# STM32MP21_CM33 register map
File version: 0.4
CPU: CM33 r0p1, little endian, MPU, FPU, vendor SysTick, 8 interrupt priority bits
Registers are 32-bit, read-write, reset 0x0 unless marked. A register's access mark holds for its fields unless they carry their own. Offsets are from the block's base; [hi:lo] are bit positions; 'fields as' and 'values as' point back to an identical list.

## RAMCFG — RAMCFG register bank
Base 0x42070000
Same registers: RAMCFG_S 0x52070000
0x00 RAMCFG_SYSRAMCR — RAMCFG SYSRAM control register
  [8] SRAMER — SRAM erase
    0=No erase operation ongoing; 1=Erase operation ongoing
0x08 RAMCFG_SYSRAMISR ro — RAMCFG SYSRAM interrupt status register
  [8] SRAMBUSY — SRAM busy with erase operation
    0=No erase operation ongoing; 1=Erase operation ongoing
0x28 RAMCFG_SYSRAMERKEYR wo — RAMCFG SYSRAM erase key register
  [7:0] ERASEKEY — Erase write protection key
0x80 RAMCFG_SRAM1CR — RAMCFG SRAM1 control register
  [8] SRAMER — SRAM erase.
    0=No erase operation ongoing; 1=Erase operation ongoing
0x88 RAMCFG_SRAM1ISR ro — RAMCFG SRAM1 interrupt status register
  fields as RAMCFG_SYSRAMISR
0xA8 RAMCFG_SRAM1ERKEYR wo — RAMCFG SRAM1 erase key register
  [7:0] ERASEKEY — Erase write protection key
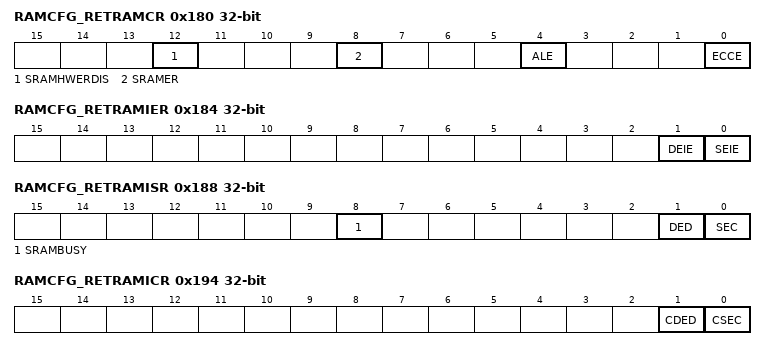
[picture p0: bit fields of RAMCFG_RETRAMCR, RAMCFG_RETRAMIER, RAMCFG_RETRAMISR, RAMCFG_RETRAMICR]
0x180 RAMCFG_RETRAMCR — RAMCFG RETRAM control register
  [12] SRAMHWERDIS — SRAM hardware erase disable
    0=Erase operation done after a system reset; 1=No erase operation done after a system reset
  [8] SRAMER — SRAM erase.
    0=No erase operation ongoing; 1=Erase operation ongoing
  [4] ALE — Address latch enable
    0=Failing address not stored in the RETRAMECC single/double error address registers; 1=Failing address stored in the RETRAMECC single/double error address registers
  [0] ECCE — ECC enable
    0=ECC disabled; 1=ECC enabled
0x184 RAMCFG_RETRAMIER — RAMCFG RETRAM interrupt enable register
  [1] DEIE — ECC double error interrupt enable
    0=Double error interrupt disabled; 1=Double error interrupt enabled
  [0] SEIE — ECC single error interrupt enable
    0=Single error interrupt disabled; 1=Single error interrupt enabled
0x188 RAMCFG_RETRAMISR ro — RAMCFG RETRAM interrupt status register
  [8] SRAMBUSY — SRAM busy with erase operation
    0=No erase operation ongoing; 1=Erase operation ongoing
  [1] DED — ECC double error detected
    0=No double error; 1=Double error detected
  [0] SEC — ECC single error corrected
    0=No single error; 1=Single error corrected
0x18C RAMCFG_RETRAMSEAR ro — RAMCFG RETRAM ECC single error address register
  [14:0] ESEA — ECC single error address
0x190 RAMCFG_RETRAMDEAR ro — RAMCFG RETRAM ECC double error address register
  [14:0] EDEA — ECC double error address
0x194 RAMCFG_RETRAMICR wo — RAMCFG RETRAM interrupt clear flag register
  [1] CDED — Clear of ECC double error detected
  [0] CSEC — Clear of ECC single corrected
0x1A4 RAMCFG_RETRAMECCKEYR wo — RAMCFG RETRAM ECC key register
  [7:0] ECCKEY — ECC write protection key
0x1A8 RAMCFG_RETRAMERKEYR wo — RAMCFG RETRAM erase key register
  [7:0] ERASEKEY — Erase write protection key
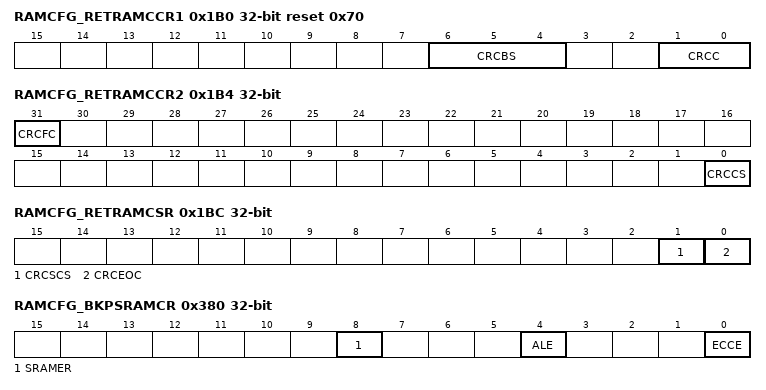
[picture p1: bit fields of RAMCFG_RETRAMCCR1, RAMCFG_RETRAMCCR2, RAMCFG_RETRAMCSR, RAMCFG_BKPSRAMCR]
0x1B0 RAMCFG_RETRAMCCR1 reset 0x70 — RAMCFG RETRAM CRC control register 1
  [6:4] CRCBS — CRC buffer size
    0=16 Kbytes; 1=32 Kbytes; 2=48 Kbytes; 7=128 Kbytes (default)
  [1:0] CRCC — CRC configuration.
    0=CRC disabled; 1=CRC computation enabled; 2=CRC computation and signature check enabled
0x1B4 RAMCFG_RETRAMCCR2 — RAMCFG RETRAM CRC control register 2
  [31] CRCFC — CRC flags clear.
    0=CRC flags are not affected; 1=CRC flags are cleared in RAMCFG_RETRAMCSR
  [0] CRCCS — CRC computation start
    0=CRC computation not launched; 1=CRC computation launched
0x1B8 RAMCFG_RETRAMCRSR — RAMCFG RETRAM CRC reference signature register
  [31:0] CRCRS — CRC reference signature.
0x1BC RAMCFG_RETRAMCSR ro — RAMCFG RETRAM CRC status register
  [1] CRCSCS — CRC signature check status flag
    0=Fault detected is SRAM data; 1=SRAM data is correct
  [0] CRCEOC — CRC end-of-computation flag
    0=Computation ongoing; 1=Computation done
0x1C0 RAMCFG_RETRAMCCSR ro — RAMCFG RETRAM CRC calculated signature register
  [31:0] CRCCS — CRC calculated signature
0x380 RAMCFG_BKPSRAMCR — RAMCFG BKPSRAM control register
  [8] SRAMER — SRAM erase.
    0=No erase operation ongoing; 1=Erase operation ongoing
  [4] ALE — Address latch enable
    0=Failing address not stored in the BKPSRAMECC single/double error address registers; 1=Failing address stored in the BKPSRAMECC single/double error address registers
  [0] ECCE — ECC enable
    0=ECC disabled; 1=ECC enabled
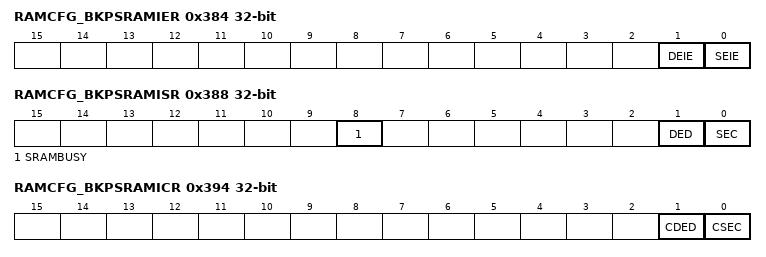
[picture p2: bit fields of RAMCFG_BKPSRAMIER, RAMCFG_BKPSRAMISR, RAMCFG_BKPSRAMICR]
0x384 RAMCFG_BKPSRAMIER — RAMCFG BKPSRAM interrupt enable register
  [1] DEIE — ECC double-error interrupt enable
    0=Double-error interrupt disabled; 1=Double-error interrupt enabled
  [0] SEIE — ECC single-error interrupt enable
    0=Single-error interrupt disabled; 1=Single-error interrupt enabled
0x388 RAMCFG_BKPSRAMISR ro — RAMCFG BKPSRAM interrupt status register
  [8] SRAMBUSY — SRAM busy with erase operation
    0=No erase operation ongoing; 1=Erase operation ongoing
  [1] DED — ECC double error detected
    0=No double error; 1=Double error detected
  [0] SEC — ECC single error corrected
    0=No single error; 1=Single error detected and corrected
0x38C RAMCFG_BKPSRAMEEAR ro — RAMCFG BKPSRAM ECC single error address register
  [10:0] ESEA — ECC single error address
0x390 RAMCFG_BKPSRAMDEAR ro — RAMCFG BKPSRAM ECC double error address register
  [10:0] EDEA — ECC double error address
0x394 RAMCFG_BKPSRAMICR wo — RAMCFG BKPSRAM interrupt clear flag register
  fields as RAMCFG_RETRAMICR
0x3A4 RAMCFG_BKPSRAMECCKEYR wo — RAMCFG BKPSRAM ECC key register
  [7:0] ECCKEY — ECC write protection key
0x3A8 RAMCFG_BKPSRAMERKEYR wo — RAMCFG BKPSRAM erase key register
  [7:0] ERASEKEY — Erase write protection key
